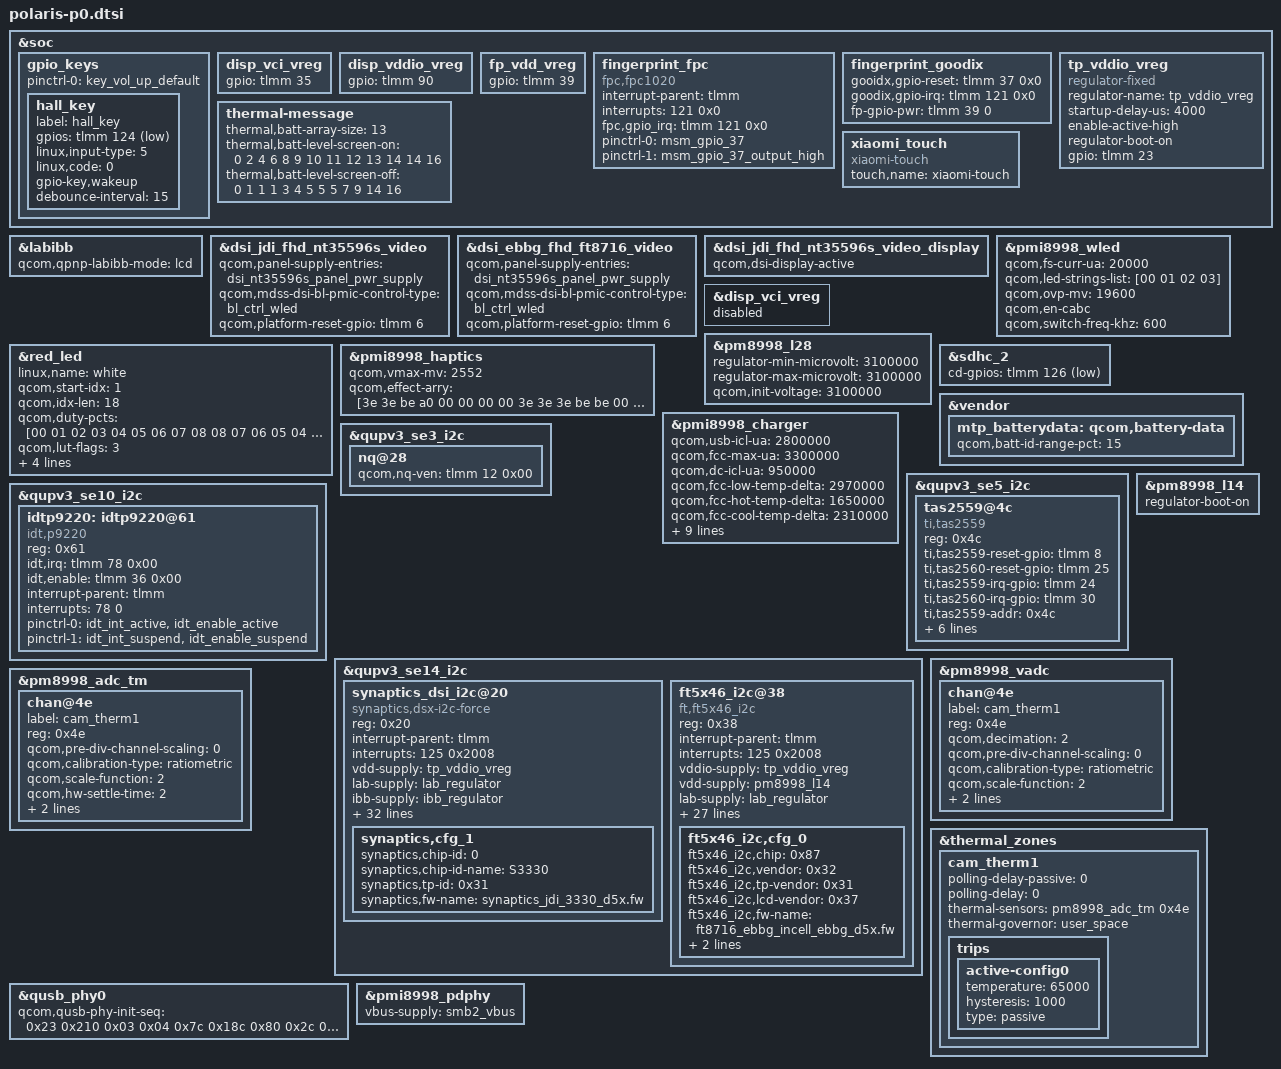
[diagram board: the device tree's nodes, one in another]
/* Copyright (c) 2016-2017, The Linux Foundation. All rights reserved.
 * Copyright (C) 2019 XiaoMi, Inc.
 *
 * This program is free software; you can redistribute it and/or modify
 * it under the terms of the GNU General Public License version 2 and
 * only version 2 as published by the Free Software Foundation.
 *
 * This program is distributed in the hope that it will be useful,
 * but WITHOUT ANY WARRANTY; without even the implied warranty of
 * MERCHANTABILITY or FITNESS FOR A PARTICULAR PURPOSE.  See the
 * GNU General Public License for more details.
 */

#include "../xiaomi-sdm845-common.dtsi"
#include "polaris-camera-sensor-mtp.dtsi"

&soc {
	gpio_keys {
		pinctrl-0 = <&key_vol_up_default>;
		hall_key {
			label = "hall_key";
			gpios = <&tlmm 124 GPIO_ACTIVE_LOW>;
			linux,input-type = <5>;
			linux,code = <0>;
			gpio-key,wakeup;
			debounce-interval = <15>;
		};
	};

	disp_vci_vreg {
		gpio = <&tlmm 35 0>;
	};

	disp_vddio_vreg {
		gpio = <&tlmm 90 0>;
	 };

	fp_vdd_vreg {
		gpio = <&tlmm 39 0>;
	};

	fingerprint_fpc {
		status = "ok";
		compatible = "fpc,fpc1020";
		interrupt-parent = <&tlmm>;
		interrupts = <121 0x0>;
		fpc,gpio_irq = <&tlmm 121 0x0>;
		/* fpc,enable-on-boot; */
		/* fpc,enable-wakeup;  */

		pinctrl-names = "fpc1020_reset_reset", "fpc1020_reset_active";

		pinctrl-0 = <&msm_gpio_37>;
		pinctrl-1 = <&msm_gpio_37_output_high>;
	};

	fingerprint_goodix {
		gooidx,gpio-reset = <&tlmm 37 0x0>;
		goodix,gpio-irq = <&tlmm 121 0x0>;
		fp-gpio-pwr = <&tlmm 39 0>;
	};

    tp_vddio_vreg: tp_vddio_vreg {
	 compatible = "regulator-fixed";
	 regulator-name = "tp_vddio_vreg";
	 startup-delay-us = <4000>;
	 enable-active-high;
	 regulator-boot-on;
	 gpio = <&tlmm 23 0>;
     };

	thermal-message {
		thermal,batt-array-size = "13";
		thermal,batt-level-screen-on = "0 2 4 6 8 9 10 11 12 13 14 14 16";
		thermal,batt-level-screen-off = "0 1 1 1 3 4 5 5 5 7 9 14 16";
	};

	xiaomi_touch {
		compatible = "xiaomi-touch";
		status = "ok";
		touch,name = "xiaomi-touch";
	};

};

&labibb {
	status = "ok";
	qcom,qpnp-labibb-mode = "lcd";
};

&dsi_jdi_fhd_nt35596s_video {
	qcom,panel-supply-entries = <&dsi_nt35596s_panel_pwr_supply>;
	qcom,mdss-dsi-bl-pmic-control-type = "bl_ctrl_wled";
	qcom,platform-reset-gpio = <&tlmm 6 0>;
};

&dsi_ebbg_fhd_ft8716_video {
	qcom,panel-supply-entries = <&dsi_nt35596s_panel_pwr_supply>;
	qcom,mdss-dsi-bl-pmic-control-type = "bl_ctrl_wled";
	qcom,platform-reset-gpio = <&tlmm 6 0>;
};

&dsi_jdi_fhd_nt35596s_video_display {
	qcom,dsi-display-active;
};

&pmi8998_wled {
	status = "okay";
	qcom,fs-curr-ua = <20000>;
	qcom,led-strings-list = [00 01 02 03];
	qcom,ovp-mv = <19600>;
	qcom,en-cabc;
	qcom,switch-freq-khz = <600>;
};

&red_led {
	linux,name = "white";
	qcom,start-idx = <1>;
	qcom,idx-len = <18>;
	qcom,duty-pcts = [00 01 02 03 04 05 06 07 08
			08 07 06 05 04 03 02 01 00];
	qcom,lut-flags = <3>;
	qcom,pause-lo = <0>;
	qcom,pause-hi = <0>;
	qcom,ramp-step-ms = <142>;
	qcom,use-blink;
	status = "okay";
};

&disp_vci_vreg {
	status = "disabled";
};

&pmi8998_haptics {
	qcom,vmax-mv = <2552>;
	qcom,effect-arry = [3e 3e be a0 00 00 00 00
	3e 3e 3e be be 00 00 00
	3e 3e 3e 3e be be a0 90];
};

&pm8998_l28{
	regulator-min-microvolt = <3100000>;
	regulator-max-microvolt = <3100000>;
	qcom,init-voltage = <3100000>;
};

&sdhc_2 {
	cd-gpios = <&tlmm 126 GPIO_ACTIVE_LOW>;
};

&vendor{
	mtp_batterydata: qcom,battery-data {
		qcom,batt-id-range-pct = <15>;
		#include "../battery/batterydata-d5-atl-3400mAh.dtsi"
		#include "../battery/batterydata-d5-cos-3400mAh.dtsi"
		#include "../battery/batterydata-itech-3020mAh.dtsi"
	};
};

&pmi8998_charger {
	qcom,usb-icl-ua = <2800000>;
	qcom,fcc-max-ua = <3300000>;
	qcom,dc-icl-ua = <950000>;
	qcom,fcc-low-temp-delta = <2970000>;
	qcom,fcc-hot-temp-delta = <1650000>;
	qcom,fcc-cool-temp-delta = <2310000>;
	qcom,wireless-flag;
	qcom,wireless-support;
	qcom,thermal-mitigation-dc
				= <800000 550000 450000 325000>;
	qcom,thermal-mitigation-qc3
				= <2800000 2725000 2575000 2425000 2275000 2125000 2000000
				   1800000 1650000 1500000 1360000 1200000 1060000 900000
				   752500 525000>;

	io-channels = <&pmi8998_rradc 8>,
		<&pmi8998_rradc 10>,
		<&pmi8998_rradc 3>,
		<&pmi8998_rradc 4>,
		<&pmi8998_rradc 5>;
	io-channel-names = "charger_temp",
		"charger_temp_max",
		"usbin_i",
		"usbin_v",
		"dcin_i";
};

&qupv3_se3_i2c {
	status = "ok";
	nq@28 {
		qcom,nq-ven = <&tlmm 12 0x00>;
	};
};

&qupv3_se5_i2c {
	status = "ok";
	/*smart PA*/
	tas2559@4c{
		compatible = "ti,tas2559";
		reg = <0x4c>;
		ti,tas2559-reset-gpio = <&tlmm 8 0>;
		ti,tas2560-reset-gpio = <&tlmm 25 0>;
		ti,tas2559-irq-gpio = <&tlmm 24 0>;
		ti,tas2560-irq-gpio = <&tlmm 30 0>;
		ti,tas2559-addr = <0x4c>;
		ti,tas2560-addr = <0x4d>;
		ti,tas2559-channel = <0>; /* 0, left; 1, right */
		ti,tas2560-channel = <1>; /* 0, left; 1, right */
		ti,ycrc-enable = <1>;           /* 0, disable; non-zero, enable */
		ti,echo-ref = <0>;              /* 0, left channel; 1, right channel; 2, both */
		ti,bit-rate = <16>;             /* 16, 20, 24, 32 */
		status = "ok";
	};

};

&qupv3_se10_i2c {
	status = "ok";
	idtp9220: idtp9220@61 {
		compatible = "idt,p9220";
		reg = <0x61>;
		idt,irq = <&tlmm 78 0x00>;
		idt,enable = <&tlmm 36 0x00>;
		interrupt-parent = <&tlmm>;
		interrupts = <78 0>;
		interrupt-names = "idt_irq";
		pinctrl-names = "idt_active", "idt_suspend";
		pinctrl-0 = <&idt_int_active &idt_enable_active>;
		pinctrl-1 = <&idt_int_suspend &idt_enable_suspend>;
	};
};

&qupv3_se14_i2c {
	status = "ok";
	synaptics_dsi_i2c@20 {
		compatible = "synaptics,dsx-i2c-force";
		reg = <0x20>;
		interrupt-parent = <&tlmm>;
		interrupts = <125 0x2008>;
		vdd-supply = <&tp_vddio_vreg>;
		lab-supply = <&lab_regulator>;
		ibb-supply = <&ibb_regulator>;
		disp-supply = <&pm8998_l14>;
		avdd-supply = <&pm8998_l28>;
		synaptics,pwr-reg-name = "vdd";
		synaptics,lab-reg-name = "lab";
		synaptics,ibb-reg-name = "ibb";
		synaptics,disp-reg-name = "disp";
		synaptics,bus-reg-name = "avdd";
		synaptics,disp-power-hold;
		synaptics,ub-i2c-addr = <0x2c>;
		pinctrl-names = "pmx_ts_active", "pmx_ts_suspend";
		pinctrl-0 = <&ts_active>;
		pinctrl-1 = <&ts_int_suspend &ts_reset_suspend>;
		/*synaptics,palm-rx-channel = <10>;*/
		/*synaptics,palm-rx-area = <400>;*/
		/*synaptics,palm-tx-disable = <4>;*/
		synaptics,drm-dsi-reset = <&tlmm 6 0>;
		synaptics,reset-gpio = <&tlmm 99 0x00>;
		synaptics,irq-gpio = <&tlmm  125 0x2008>;
		synaptics,reset-gpio-name = "dsx_reset";
		synaptics,irq-gpio-name = "dsx_irq";
		synaptics,irq-on-state = <0>;
		synaptics,irq-flags = <0x2008>; /* IRQF_ONESHOT | IRQF_TRIGGER_LOW */
		synaptics,power-delay-ms = <5>;
		synaptics,reset-delay-ms = <200>;
		synaptics,reset-active-ms = <5>;
		synaptics,power-on-state = <1>;
		synaptics,reset-on-state = <0>;
		synaptics,drm-reset-state = <1>;
		synaptics,panel-is-incell;
		synaptics,short-jdi-25 = "000: 0xff\n001: 0xff\n002: 0xff\n003: 0xf7\n004: 0x03\n005: 0x00\n006: 0x00";
		synaptics,short-jdi-26 = "000: 0x03\n001: 0x00\n002: 0x00\n003: 0x00\n004: 0x03\n005: 0x00\n006: 0x00";
		/*clock-names = "iface_clk", "core_clk";
		clocks = <&clock_gcc clk_gcc_blsp1_ahb_clk>,
			 <&clock_gcc clk_gcc_blsp1_qup5_i2c_apps_clk>;
			 */
		synaptics,guest-serialization-as-lockdown;
		synaptics,tp-id-byte = /bits/ 8 <0>;
		synaptics,config-array-size = <1>;
		synaptics,cfg_1 {
			synaptics,chip-id = <0>;
			synaptics,chip-id-name = "S3330";
			synaptics,tp-id = /bits/ 8 <0x31>;
			synaptics,fw-name = "synaptics_jdi_3330_d5x.fw";
		};
	};
	ft5x46_i2c@38 {
		compatible = "ft,ft5x46_i2c";
		reg = <0x38>;
		interrupt-parent = <&tlmm>;
		interrupts = <125 0x2008>;
		vddio-supply = <&tp_vddio_vreg>;
		vdd-supply = <&pm8998_l14>;
		lab-supply = <&lab_regulator>;
		ibb-supply = <&ibb_regulator>;
		/* pins used by touchscreen */
		pinctrl-names = "pmx_ts_active","pmx_ts_suspend";
		pinctrl-0 = <&ts_active>;
		pinctrl-1 = <&ts_int_suspend &ts_reset_suspend>;
		ft5x46_i2c,i2c-pull-up;
		ft5x46_i2c,irqflags = <0x2008>;
		ft5x46_i2c,x-max = <1080>;
		ft5x46_i2c,y-max = <2160>;
		ft5x46_i2c,z-max = <255>;
		ft5x46_i2c,w-max = <200>;
		ft5x46_i2c,reset-gpio = <&tlmm 99 0x00>;
		ft5x46_i2c,irq-gpio = <&tlmm 125 0x2008>;
		ft5x46_i2c,skip-reset-in-resume;
		ft5x46_i2c,landing-jiffies = <1000>;
		ft5x46_i2c,landing-threshold = <16>;
		ft5x46_i2c,staying-threshold = <8>;
		ft5x46_i2c,raw-min = <7000>;
		ft5x46_i2c,raw-max = <10000>;
		ft5x46_i2c,open-min = <60>;
		ft5x46_i2c,open-max = <200>;
		ft5x46_i2c,short-min = <200>;
		ft5x46_i2c,short-max = <100000000>;
		ft5x46_i2c,fw-delay-55-ms = <2>;
		ft5x46_i2c,fw-delay-aa-ms = <2>;
		ft5x46_i2c,fw-upgrade-id1 = <0xE7>;
		ft5x46_i2c,fw-upgrade-id2 = <0xA6>;
		ft5x46_i2c,fw-delay-readid-ms = <20>;
		ft5x46_i2c,firmware-array-size = <1>;
		ft5x46_i2c,cfg_0 {
			ft5x46_i2c,chip = <0x87>;
			ft5x46_i2c,vendor = <0x32>;
			ft5x46_i2c,tp-vendor = <0x31>;
			ft5x46_i2c,lcd-vendor = <0x37>;
			ft5x46_i2c,fw-name = "ft8716_ebbg_incell_ebbg_d5x.fw";
			ft5x46_i2c,tx-num = <24>;
			ft5x46_i2c,rx-num = <13>;
		};
	};

};

&pm8998_l14 {
	regulator-boot-on;
};

&pm8998_vadc {
	chan@4e {
		label = "cam_therm1";
		reg = <0x4e>;
		qcom,decimation = <2>;
		qcom,pre-div-channel-scaling = <0>;
		qcom,calibration-type = "ratiometric";
		qcom,scale-function = <2>;
		qcom,hw-settle-time = <2>;
		qcom,fast-avg-setup = <0>;
	};
};

&pm8998_adc_tm {
	chan@4e {
		label = "cam_therm1";
		reg = <0x4e>;
		qcom,pre-div-channel-scaling = <0>;
		qcom,calibration-type = "ratiometric";
		qcom,scale-function = <2>;
		qcom,hw-settle-time = <2>;
		qcom,btm-channel-number = <0x70>;
		qcom,thermal-node;
	};
};

&thermal_zones {
	cam_therm1 {
		polling-delay-passive = <0>;
		polling-delay = <0>;
		thermal-sensors = <&pm8998_adc_tm 0x4e>;
		thermal-governor = "user_space";

		trips {
			active-config0 {
					temperature = <65000>;
					hysteresis = <1000>;
					type = "passive";
			};
		};
	};
};

&qusb_phy0 {
	qcom,qusb-phy-init-seq =
		/* <value reg_offset> */
		   <0x23 0x210 /* PWR_CTRL1 */
		    0x03 0x04  /* PLL_ANALOG_CONTROLS_TWO */
		    0x7c 0x18c /* PLL_CLOCK_INVERTERS */
		    0x80 0x2c  /* PLL_CMODE */
		    0x0a 0x184 /* PLL_LOCK_DELAY */
		    0x19 0xb4  /* PLL_DIGITAL_TIMERS_TWO */
		    0x40 0x194 /* PLL_BIAS_CONTROL_1 */
		    0x12 0x198 /* PLL_BIAS_CONTROL_2 */
		    0x21 0x214 /* PWR_CTRL2 */
		    0x08 0x220 /* IMP_CTRL1 */
		    0x58 0x224 /* IMP_CTRL2 */
		    0x07 0x240 /* TUNE1 */
		    0x2b 0x244 /* TUNE2 */
		    0xca 0x248 /* TUNE3 */
		    0x04 0x24c /* TUNE4 */
		    0x03 0x250 /* TUNE5 */
		    0x00 0x23c /* CHG_CTRL2 */
		    0x22 0x210>; /* PWR_CTRL1 */
};

&pmi8998_pdphy {
	vbus-supply = <&smb2_vbus>;
};
